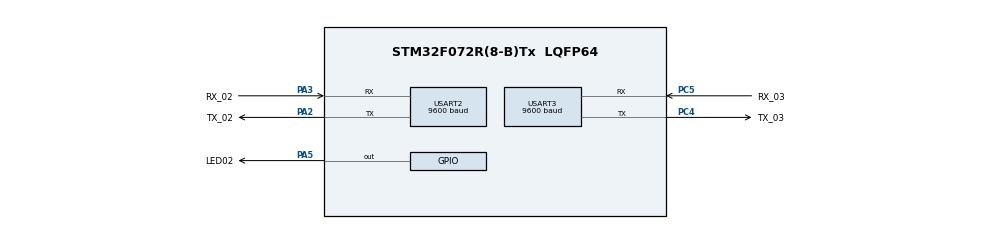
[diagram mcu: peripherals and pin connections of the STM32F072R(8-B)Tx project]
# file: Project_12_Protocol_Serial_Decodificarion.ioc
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Mcu.Family=STM32F0
Mcu.Name=STM32F072R(8-B)Tx
Mcu.Package=LQFP64
NVIC.USART2_IRQn=true\:0\:0\:false\:false\:true\:true\:true\:true
NVIC.USART3_4_IRQn=true\:0\:0\:false\:false\:true\:true\:true\:true
PA2.GPIO_Label=TX_02
PA2.Mode=Asynchronous
PA2.Signal=USART2_TX
PA3.GPIO_Label=RX_02
PA3.Mode=Asynchronous
PA3.Signal=USART2_RX
PA5.GPIO_Label=LED02
PA5.Signal=GPIO_Output
PC4.GPIO_Label=TX_03
PC4.Mode=Asynchronous
PC4.Signal=USART3_TX
PC5.GPIO_Label=RX_03
PC5.Mode=Asynchronous
PC5.Signal=USART3_RX
ProjectManager.HeapSize=0x200
ProjectManager.StackSize=0x400
ProjectManager.TargetToolchain=STM32CubeIDE
USART2.BaudRate=9600
USART2.VirtualMode-Asynchronous=VM_ASYNC
USART3.BaudRate=9600
USART3.VirtualMode-Asynchronous=VM_ASYNC
VP_CRC_VS_CRC.Mode=CRC_Activate
board=custom

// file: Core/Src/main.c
/* USER CODE BEGIN Header */
/**
  ******************************************************************************
  * @file           : main.c
  * @brief          : Main program body
  ******************************************************************************
  * @attention
  *
  * Copyright (c) 2022 STMicroelectronics.
  * All rights reserved.
  *
  * This software is licensed under terms that can be found in the LICENSE file
  * in the root directory of this software component.
  * If no LICENSE file comes with this software, it is provided AS-IS.
  *
  ******************************************************************************
  */
/* USER CODE END Header */
#include "main.h"

/* USER CODE BEGIN Includes */

#include "stdio.h"
#include "math.h"
#include "stdlib.h"

/* USER CODE END Includes */

CRC_HandleTypeDef hcrc;

UART_HandleTypeDef huart2;
UART_HandleTypeDef huart3;

void SystemClock_Config(void);
static void MX_GPIO_Init(void);
static void MX_CRC_Init(void);
static void MX_USART2_UART_Init(void);
static void MX_USART3_UART_Init(void);

int main(void)
{

  /* MCU Configuration--------------------------------------------------------*/

  /* Reset of all peripherals, Initializes the Flash interface and the Systick. */
  HAL_Init();

  /* Configure the system clock */
  SystemClock_Config();

  /* Initialize all configured peripherals */
  MX_GPIO_Init();
  MX_CRC_Init();
  MX_USART2_UART_Init();
  MX_USART3_UART_Init();

  /* Infinite loop */
  while (1)
  {

	  uint8_t Informacao_Recebida[99]= {0};

	  unsigned char *Informacao_Tratada;

	  int   Num_elementos = 0;

	  int V_Contro_Info_Tratada = 0;

	  HAL_Delay(100);

	  HAL_UART_Receive_IT(&huart2, Informacao_Recebida,100);

	  HAL_Delay(100);

	  for (int y = 0; y <= sizeof(Informacao_Recebida); y++)
	  {

		  if (Informacao_Recebida[y] != '\0')
		  {

			  Num_elementos++;

		  }

	  }

	  Informacao_Tratada = (unsigned char*) malloc(Num_elementos * sizeof(unsigned char));

	  for (int i = 0; i < Num_elementos; i++)
	  {

		  if (Informacao_Recebida[i] != '\0')
		  {

			  Informacao_Tratada[V_Contro_Info_Tratada] = Informacao_Recebida[i];

			  V_Contro_Info_Tratada++;
		  }

		  Informacao_Recebida[i] = 0;

	  }

	  if (Informacao_Tratada[0] != '\0')
	  {
		  HAL_UART_Transmit(&huart2, Informacao_Tratada, Num_elementos, 100);

	  }

  }
}

void SystemClock_Config(void)
{
  RCC_OscInitTypeDef RCC_OscInitStruct = {0};
  RCC_ClkInitTypeDef RCC_ClkInitStruct = {0};
  RCC_PeriphCLKInitTypeDef PeriphClkInit = {0};

  /** Initializes the RCC Oscillators according to the specified parameters
  * in the RCC_OscInitTypeDef structure.
  */
  RCC_OscInitStruct.OscillatorType = RCC_OSCILLATORTYPE_HSI;
  RCC_OscInitStruct.HSIState = RCC_HSI_ON;
  RCC_OscInitStruct.HSICalibrationValue = RCC_HSICALIBRATION_DEFAULT;
  RCC_OscInitStruct.PLL.PLLState = RCC_PLL_NONE;
  if (HAL_RCC_OscConfig(&RCC_OscInitStruct) != HAL_OK)
  {
    Error_Handler();
  }

  /** Initializes the CPU, AHB and APB buses clocks
  */
  RCC_ClkInitStruct.ClockType = RCC_CLOCKTYPE_HCLK|RCC_CLOCKTYPE_SYSCLK
                              |RCC_CLOCKTYPE_PCLK1;
  RCC_ClkInitStruct.SYSCLKSource = RCC_SYSCLKSOURCE_HSI;
  RCC_ClkInitStruct.AHBCLKDivider = RCC_SYSCLK_DIV1;
  RCC_ClkInitStruct.APB1CLKDivider = RCC_HCLK_DIV1;

  if (HAL_RCC_ClockConfig(&RCC_ClkInitStruct, FLASH_LATENCY_0) != HAL_OK)
  {
    Error_Handler();
  }
  PeriphClkInit.PeriphClockSelection = RCC_PERIPHCLK_USART2;
  PeriphClkInit.Usart2ClockSelection = RCC_USART2CLKSOURCE_PCLK1;
  if (HAL_RCCEx_PeriphCLKConfig(&PeriphClkInit) != HAL_OK)
  {
    Error_Handler();
  }
}

static void MX_CRC_Init(void)
{

  hcrc.Instance = CRC;
  hcrc.Init.DefaultPolynomialUse = DEFAULT_POLYNOMIAL_ENABLE;
  hcrc.Init.DefaultInitValueUse = DEFAULT_INIT_VALUE_ENABLE;
  hcrc.Init.InputDataInversionMode = CRC_INPUTDATA_INVERSION_NONE;
  hcrc.Init.OutputDataInversionMode = CRC_OUTPUTDATA_INVERSION_DISABLE;
  hcrc.InputDataFormat = CRC_INPUTDATA_FORMAT_BYTES;
  if (HAL_CRC_Init(&hcrc) != HAL_OK)
  {
    Error_Handler();
  }

}

static void MX_USART2_UART_Init(void)
{

  huart2.Instance = USART2;
  huart2.Init.BaudRate = 9600;
  huart2.Init.WordLength = UART_WORDLENGTH_8B;
  huart2.Init.StopBits = UART_STOPBITS_1;
  huart2.Init.Parity = UART_PARITY_NONE;
  huart2.Init.Mode = UART_MODE_TX_RX;
  huart2.Init.HwFlowCtl = UART_HWCONTROL_NONE;
  huart2.Init.OverSampling = UART_OVERSAMPLING_16;
  huart2.Init.OneBitSampling = UART_ONE_BIT_SAMPLE_DISABLE;
  huart2.AdvancedInit.AdvFeatureInit = UART_ADVFEATURE_NO_INIT;
  if (HAL_UART_Init(&huart2) != HAL_OK)
  {
    Error_Handler();
  }

}

static void MX_USART3_UART_Init(void)
{

  huart3.Instance = USART3;
  huart3.Init.BaudRate = 9600;
  huart3.Init.WordLength = UART_WORDLENGTH_8B;
  huart3.Init.StopBits = UART_STOPBITS_1;
  huart3.Init.Parity = UART_PARITY_NONE;
  huart3.Init.Mode = UART_MODE_TX_RX;
  huart3.Init.HwFlowCtl = UART_HWCONTROL_NONE;
  huart3.Init.OverSampling = UART_OVERSAMPLING_16;
  huart3.Init.OneBitSampling = UART_ONE_BIT_SAMPLE_DISABLE;
  huart3.AdvancedInit.AdvFeatureInit = UART_ADVFEATURE_NO_INIT;
  if (HAL_UART_Init(&huart3) != HAL_OK)
  {
    Error_Handler();
  }

}

static void MX_GPIO_Init(void)
{
  GPIO_InitTypeDef GPIO_InitStruct = {0};

  /* GPIO Ports Clock Enable */
  __HAL_RCC_GPIOA_CLK_ENABLE();
  __HAL_RCC_GPIOC_CLK_ENABLE();

  /*Configure GPIO pin Output Level */
  HAL_GPIO_WritePin(LED02_GPIO_Port, LED02_Pin, GPIO_PIN_RESET);

  /*Configure GPIO pin : LED02_Pin */
  GPIO_InitStruct.Pin = LED02_Pin;
  GPIO_InitStruct.Mode = GPIO_MODE_OUTPUT_PP;
  GPIO_InitStruct.Pull = GPIO_NOPULL;
  GPIO_InitStruct.Speed = GPIO_SPEED_FREQ_LOW;
  HAL_GPIO_Init(LED02_GPIO_Port, &GPIO_InitStruct);

}

void Error_Handler(void)
{
  __disable_irq();
  while (1)
  {
  }
}
